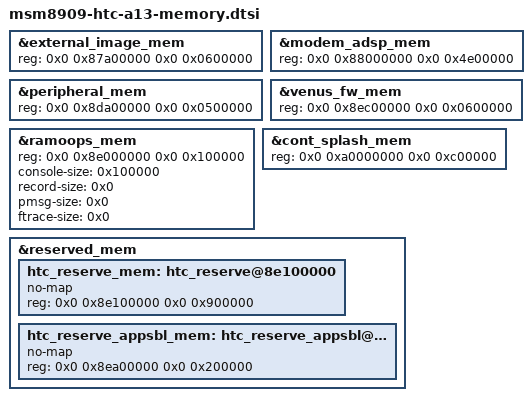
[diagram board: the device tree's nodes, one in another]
/* Copyright (c) 2016, The Linux Foundation. All rights reserved.
 *
 * This program is free software; you can redistribute it and/or modify
 * it under the terms of the GNU General Public License version 2 and
 * only version 2 as published by the Free Software Foundation.
 *
 * This program is distributed in the hope that it will be useful,
 * but WITHOUT ANY WARRANTY; without even the implied warranty of
 * MERCHANTABILITY or FITNESS FOR A PARTICULAR PURPOSE.  See the
 * GNU General Public License for more details.
 */

&external_image_mem {
	reg = <0x0 0x87a00000 0x0 0x0600000>;
};

&modem_adsp_mem {
	reg = <0x0 0x88000000 0x0 0x4e00000>;
};

&peripheral_mem {
	reg = <0x0 0x8da00000 0x0 0x0500000>;
};

&venus_fw_mem {
	reg = <0x0 0x8ec00000 0x0 0x0600000>;
};

&ramoops_mem {
	reg = <0x0 0x8e000000 0x0 0x100000>;
	console-size = <0x100000>;
	record-size = <0x0>;
	pmsg-size = <0x0>;
	ftrace-size = <0x0>;
};

&cont_splash_mem {
	reg = <0x0 0xa0000000 0x0 0xc00000>;
};

&reserved_mem {
	htc_reserve_mem: htc_reserve@8e100000 {
		no-map;
		reg = <0x0 0x8e100000 0x0 0x900000>;
	};

	htc_reserve_appsbl_mem: htc_reserve_appsbl@8ea00000 {
		no-map;
		reg = <0x0 0x8ea00000 0x0 0x200000>;
	};
};
